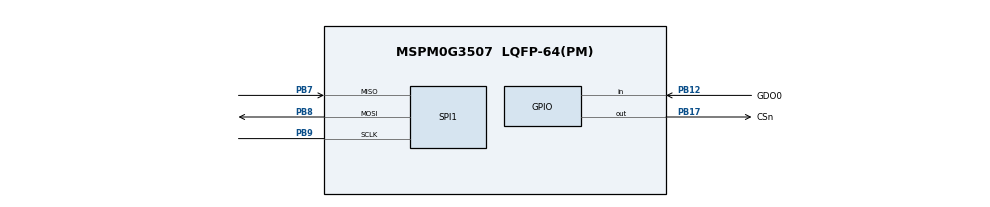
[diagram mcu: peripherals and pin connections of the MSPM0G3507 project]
//@cliArgs --device "MSPM0G350X" --package "LQFP-64(PM)" --part "Default"
//@v2CliArgs --device "MSPM0G3507" --package "LQFP-64(PM)"
// @cliArgs --board /ti/boards/LP_MSPM0G3507 --rtos nortos

/**
 * Import the modules used in this configuration.
 */
const GPIO   = scripting.addModule("/ti/driverlib/GPIO", {}, false);
const GPIO1  = GPIO.addInstance();
const GPIO2  = GPIO.addInstance();
const GPIO3  = GPIO.addInstance();
const GPIO4  = GPIO.addInstance();
const SPI    = scripting.addModule("/ti/driverlib/SPI", {}, false);
const SPI1   = SPI.addInstance();
const SYSCTL = scripting.addModule("/ti/driverlib/SYSCTL");

/**
 * Write custom configuration values to the imported modules.
 */
GPIO1.port                           = "PORTB";
GPIO1.$name                          = "GPIO_SPI_0";
GPIO1.associatedPins[0].initialValue = "SET";
GPIO1.associatedPins[0].ioStructure  = "SD";
GPIO1.associatedPins[0].$name        = "CSn";
GPIO1.associatedPins[0].pin.$assign  = "PB17";

const Board = scripting.addModule("/ti/driverlib/Board", {}, false);

GPIO2.$name                               = "GPIO_LED";
GPIO2.associatedPins[0].launchPadShortcut = "LED2GreenEn";
GPIO2.associatedPins[0].$name             = "GLED";

GPIO3.$name                                 = "GPIO_INPUT";
GPIO3.associatedPins[0].direction           = "INPUT";
GPIO3.associatedPins[0].assignedPortSegment = "Lower";
GPIO3.associatedPins[0].interruptEn         = true;
GPIO3.associatedPins[0].polarity            = "FALL";
GPIO3.associatedPins[0].assignedPort        = "PORTB";
GPIO3.associatedPins[0].$name               = "GDO0";
GPIO3.associatedPins[0].pin.$assign         = "PB12";

GPIO4.$name                               = "GPIO_BUTTON";
GPIO4.associatedPins[0].interruptEn       = true;
GPIO4.associatedPins[0].polarity          = "FALL";
GPIO4.associatedPins[0].launchPadShortcut = "Button3En";
GPIO4.associatedPins[0].$name             = "S2";

SPI1.$name                      = "SPI_0";
SPI1.targetBitRate              = 100000;
SPI1.enabledInterrupts          = ["RX"];
SPI1.chipSelect                 = ["1"];
SPI1.rxFifoThreshold            = "DL_SPI_RX_FIFO_LEVEL_ONE_FRAME";
SPI1.txFifoThreshold            = "DL_SPI_TX_FIFO_LEVEL_EMPTY";
SPI1.frameFormat                = "MOTO3";
SPI1.peripheral.$assign         = "SPI1";
SPI1.peripheral.sclkPin.$assign = "PB9";
SPI1.peripheral.mosiPin.$assign = "PB8";
SPI1.peripheral.misoPin.$assign = "PB7";

SYSCTL.forceDefaultClkConfig = true;
SYSCTL.clockTreeEn           = true;
